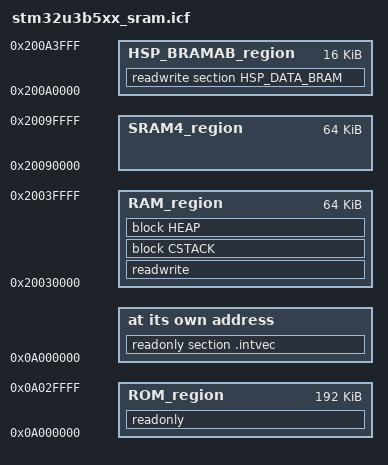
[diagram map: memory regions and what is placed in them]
/*###ICF### Section handled by ICF editor, don't touch! ****/
/*-Editor annotation file-*/
/* IcfEditorFile="$TOOLKIT_DIR$\config\ide\IcfEditor\cortex_v1_0.xml" */
/*-Specials-*/
define symbol __ICFEDIT_intvec_start__ = 0x0A000000;
/*-Memory Regions-*/
define symbol __ICFEDIT_region_ROM_start__ = 0x0A000000;
define symbol __ICFEDIT_region_ROM_end__   = 0x0A02FFFF;
define symbol __ICFEDIT_region_RAM_start__ = 0x20030000;
define symbol __ICFEDIT_region_RAM_end__   = 0x2003FFFF;
define symbol __region_SRAM4_start__       = 0x20090000;
define symbol __region_SRAM4_end__         = 0x2009FFFF;
define symbol __region_HSP_BRAMAB_start__  = 0x200A0000;
define symbol __region_HSP_BRAMAB_end__    = 0x200A3FFF;

/*-Sizes-*/
define symbol __ICFEDIT_size_cstack__ = 0x400;
define symbol __ICFEDIT_size_heap__   = 0x200;
/**** End of ICF editor section. ###ICF###*/


define memory mem with size = 4G;
define region ROM_region        = mem:[from __ICFEDIT_region_ROM_start__  to __ICFEDIT_region_ROM_end__];
define region RAM_region        = mem:[from __ICFEDIT_region_RAM_start__  to __ICFEDIT_region_RAM_end__];
define region SRAM4_region      = mem:[from __region_SRAM4_start__        to __region_SRAM4_end__];
define region HSP_BRAMAB_region = mem:[from __region_HSP_BRAMAB_start__   to __region_HSP_BRAMAB_end__];

define block CSTACK    with alignment = 8, size = __ICFEDIT_size_cstack__   { };
define block HEAP      with alignment = 8, size = __ICFEDIT_size_heap__     { };

initialize by copy { readwrite };
do not initialize  { section .noinit };

place at address mem:__ICFEDIT_intvec_start__ { readonly section .intvec };

place in ROM_region   { readonly };
place in RAM_region   { readwrite,
                        block CSTACK, block HEAP };
place in HSP_BRAMAB_region { readwrite section HSP_DATA_BRAM };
